# PADCFG_CTRL_MCU_PADCFG_CTRL_MMR_CFG0_04080000h register map
Vendor: Texas Instruments
Peripheral module from a debugger description file (folder AM275x).
Registers are 32-bit, access per field, reset 0x214007 unless marked. A register's access mark holds for its fields unless they carry their own. Offsets are as the file gives them; lines under a group give offsets from that group; [hi:lo] are bit positions; {n}, {i} and the like mark numbered series; 'fields as' and 'values as' point back to an identical list; <NAME> marks a mode.

## mcu_padcfg_ctrl_mmr_CFG0 (part 1 of 3)
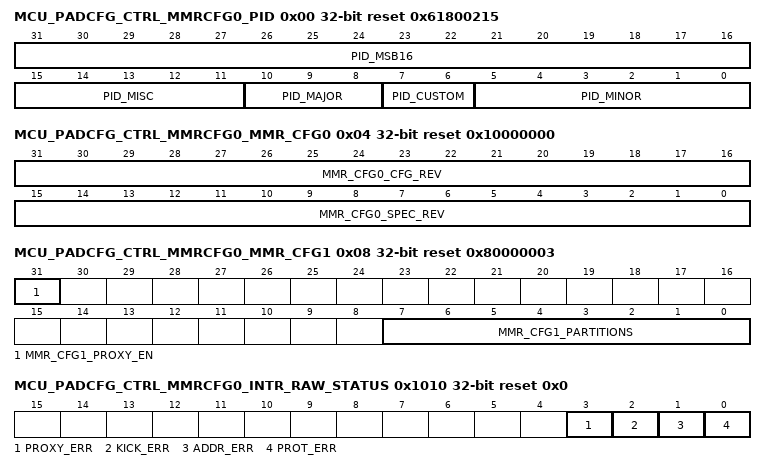
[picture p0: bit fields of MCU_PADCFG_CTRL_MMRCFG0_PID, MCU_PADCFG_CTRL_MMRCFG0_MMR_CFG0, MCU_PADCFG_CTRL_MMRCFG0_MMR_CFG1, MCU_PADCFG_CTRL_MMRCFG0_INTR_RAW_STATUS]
0x00 MCU_PADCFG_CTRL_MMRCFG0_PID ro reset 0x61800215
  [31:16] PID_MSB16 — Reset Source: mod_g_rst_n
  [15:11] PID_MISC — Reset Source: mod_g_rst_n
  [10:8] PID_MAJOR — Reset Source: mod_g_rst_n
  [7:6] PID_CUSTOM — Reset Source: mod_g_rst_n
  [5:0] PID_MINOR — Reset Source: mod_g_rst_n
0x04 MCU_PADCFG_CTRL_MMRCFG0_MMR_CFG0 ro reset 0x10000000 — Indicates the version of the CFG used to create the MMR Module
  [31:16] MMR_CFG0_CFG_REV — Major configuration release Reset Source: mod_por_rst_n
  [15:0] MMR_CFG0_SPEC_REV — Minor spec-only revision. Deprecated.Was intended to reflect non-RTL updates in the printed Spec but this can't be reflected in the MMR read value without an RTL change when post RTL descriptions are pushed into the VPS. Reset Source: mod_por_rst_n
0x08 MCU_PADCFG_CTRL_MMRCFG0_MMR_CFG1 ro reset 0x80000003 — Indicates the MMR configuration
  [31] MMR_CFG1_PROXY_EN — Proxy addressing enabled Reset Source: mod_por_rst_n
  [7:0] MMR_CFG1_PARTITIONS — Indicates present partitions Reset Source: mod_por_rst_n
0x1008 MCU_PADCFG_CTRL_MMRCFG0_LOCK0_KICK0 rw reset 0x0
  [31:0] LOCK0_KICK0 — - KICK0 component Reset Source: mod_g_rst_n
0x100C MCU_PADCFG_CTRL_MMRCFG0_LOCK0_KICK1 rw reset 0x0
  [31:0] LOCK0_KICK1 — - KICK1 component Reset Source: mod_g_rst_n
0x1010 MCU_PADCFG_CTRL_MMRCFG0_INTR_RAW_STATUS access not given reset 0x0
  [3] PROXY_ERR — Proxy0 access violation error. Raw status is read. Write a 1 to set the status. Writing a 0 has no effect. Reset Source: mod_g_rst_n (access R/W1TS)
  [2] KICK_ERR — Kick access violation error. Raw status is read. Write a 1 to set the status. Writing a 0 has no effect. Reset Source: mod_g_rst_n (access R/W1TS)
  [1] ADDR_ERR — Addressing violation error. Raw status is read. Write a 1 to set the status. Writing a 0 has no effect. Reset Source: mod_g_rst_n (access R/W1TS)
  [0] PROT_ERR — Protection violation error. Raw status is read. Write a 1 to set the status. Writing a 0 has no effect. Reset Source: mod_g_rst_n (access R/W1TS)
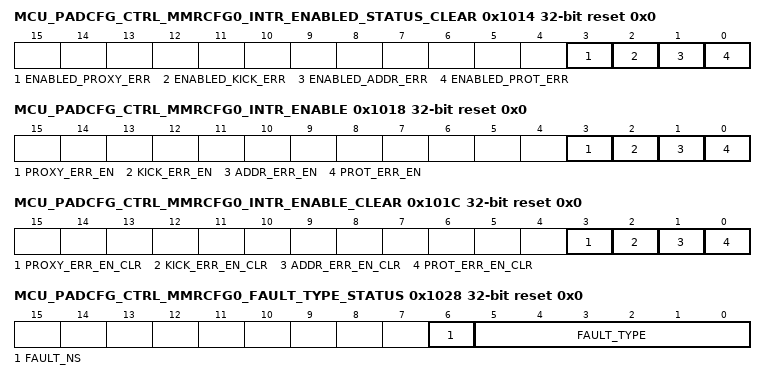
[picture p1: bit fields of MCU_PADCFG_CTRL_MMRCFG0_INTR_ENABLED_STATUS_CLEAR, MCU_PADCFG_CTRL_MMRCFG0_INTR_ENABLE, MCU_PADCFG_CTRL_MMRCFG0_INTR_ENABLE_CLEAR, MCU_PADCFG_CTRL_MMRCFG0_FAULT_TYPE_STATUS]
0x1014 MCU_PADCFG_CTRL_MMRCFG0_INTR_ENABLED_STATUS_CLEAR access not given reset 0x0
  [3] ENABLED_PROXY_ERR — Proxy0 access violation error. Enabled status is read. Write a 1 to clear the status. Writing a 0 has no effect. Reset Source: mod_g_rst_n (access R/W1TC)
  [2] ENABLED_KICK_ERR — Kick access violation error. Enabled status is read. Write a 1 to clear the status. Writing a 0 has no effect. Reset Source: mod_g_rst_n (access R/W1TC)
  [1] ENABLED_ADDR_ERR — Addressing violation error. Enabled status is read. Write a 1 to clear the status. Writing a 0 has no effect. Reset Source: mod_g_rst_n (access R/W1TC)
  [0] ENABLED_PROT_ERR — Protection violation error. Enabled status is read. Write a 1 to clear the status. Writing a 0 has no effect. Reset Source: mod_g_rst_n (access R/W1TC)
0x1018 MCU_PADCFG_CTRL_MMRCFG0_INTR_ENABLE access not given reset 0x0
  [3] PROXY_ERR_EN — Proxy0 access violation error enable. Write a 1 to set the enable. Writing a 0 has no effect. Reset Source: mod_g_rst_n (access R/W1TS)
  [2] KICK_ERR_EN — Kick access violation error enable. Write a 1 to set the enable. Writing a 0 has no effect. Reset Source: mod_g_rst_n (access R/W1TS)
  [1] ADDR_ERR_EN — Addressing violation error enable. Write a 1 to set the enable. Writing a 0 has no effect. Reset Source: mod_g_rst_n (access R/W1TS)
  [0] PROT_ERR_EN — Protection violation error enable. Write a 1 to set the enable. Writing a 0 has no effect. Reset Source: mod_g_rst_n (access R/W1TS)
0x101C MCU_PADCFG_CTRL_MMRCFG0_INTR_ENABLE_CLEAR access not given reset 0x0
  [3] PROXY_ERR_EN_CLR — Proxy0 access violation error enable clear. Write a 1 to clear the enable. Writing a 0 has no effect. Reset Source: mod_g_rst_n (access R/W1TC)
  [2] KICK_ERR_EN_CLR — Kick access violation error enable clear. Write a 1 to clear the enable. Writing a 0 has no effect. Reset Source: mod_g_rst_n (access R/W1TC)
  [1] ADDR_ERR_EN_CLR — Addressing violation error enable clear. Write a 1 to clear the enable. Writing a 0 has no effect. Reset Source: mod_g_rst_n (access R/W1TC)
  [0] PROT_ERR_EN_CLR — Protection violation error enable clear. Write a 1 to clear the enable. Writing a 0 has no effect. Reset Source: mod_g_rst_n (access R/W1TC)
0x1020 MCU_PADCFG_CTRL_MMRCFG0_EOI rw reset 0x0
  [7:0] EOI_VECTOR — EOI vector value. Write this with interrupt distribution value in the chip. Reset Source: mod_g_rst_n
0x1024 MCU_PADCFG_CTRL_MMRCFG0_FAULT_ADDRESS ro reset 0x0
  [31:0] FAULT_ADDR — Fault Address. Reset Source: mod_g_rst_n
0x1028 MCU_PADCFG_CTRL_MMRCFG0_FAULT_TYPE_STATUS ro reset 0x0
  [6] FAULT_NS — Non-secure access. Reset Source: mod_g_rst_n
  [5:0] FAULT_TYPE — Fault Type 10_0000 = Supervisor read fault - priv = 1 dir = 1 dtype != 1 01_0000 = Supervisor write fault - priv = 1 dir = 0 00_1000 = Supervisor execute fault - priv = 1 dir = 1 dtype = 1 00_0100 = User read fault - priv = 0 dir = 1 dtype = 1 00_0010 = User write fault - priv = 0 dir = 0 00_0001 = User execute fault - priv = 0 dir = 1 dtype = 1 00_0000 = No fault Reset Source: mod_g_rst_n
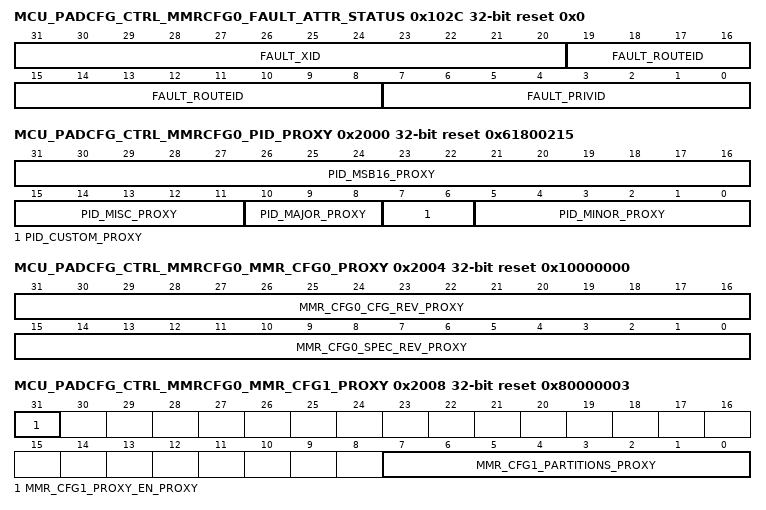
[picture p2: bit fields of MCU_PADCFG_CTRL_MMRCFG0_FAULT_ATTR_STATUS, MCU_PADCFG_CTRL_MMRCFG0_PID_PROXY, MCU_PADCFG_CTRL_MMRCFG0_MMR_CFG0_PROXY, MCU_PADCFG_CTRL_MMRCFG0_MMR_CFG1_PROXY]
0x102C MCU_PADCFG_CTRL_MMRCFG0_FAULT_ATTR_STATUS ro reset 0x0
  [31:20] FAULT_XID — XID. Reset Source: mod_g_rst_n
  [19:8] FAULT_ROUTEID — Route ID. Reset Source: mod_g_rst_n
  [7:0] FAULT_PRIVID — Privilege ID. Reset Source: mod_g_rst_n
0x1030 MCU_PADCFG_CTRL_MMRCFG0_FAULT_CLEAR wo reset 0x0
  [0] FAULT_CLR — Fault clear. Writing a 1 clears the current fault. Writing a 0 has no effect. Reset Source: mod_g_rst_n
0x1100 MCU_PADCFG_CTRL_MMRCFG0_CLAIMREG_P0_R0_READONLY ro reset 0x0
  [31:0] CLAIMREG_P0_R0_READONLY — Claim bits for Partition 0 Reset Source: mod_g_rst_n
0x2000 MCU_PADCFG_CTRL_MMRCFG0_PID_PROXY ro reset 0x61800215
  [31:16] PID_MSB16_PROXY — Reset Source: mod_g_rst_n
  [15:11] PID_MISC_PROXY — Reset Source: mod_g_rst_n
  [10:8] PID_MAJOR_PROXY — Reset Source: mod_g_rst_n
  [7:6] PID_CUSTOM_PROXY — Reset Source: mod_g_rst_n
  [5:0] PID_MINOR_PROXY — Reset Source: mod_g_rst_n
0x2004 MCU_PADCFG_CTRL_MMRCFG0_MMR_CFG0_PROXY ro reset 0x10000000 — Indicates the version of the CFG used to create the MMR Module
  [31:16] MMR_CFG0_CFG_REV_PROXY — Major configuration release Reset Source: mod_por_rst_n
  [15:0] MMR_CFG0_SPEC_REV_PROXY — Minor spec-only revision. Deprecated.Was intended to reflect non-RTL updates in the printed Spec but this can't be reflected in the MMR read value without an RTL change when post RTL descriptions are pushed into the VPS. Reset Source: mod_por_rst_n
0x2008 MCU_PADCFG_CTRL_MMRCFG0_MMR_CFG1_PROXY ro reset 0x80000003 — Indicates the MMR configuration
  [31] MMR_CFG1_PROXY_EN_PROXY — Proxy addressing enabled Reset Source: mod_por_rst_n
  [7:0] MMR_CFG1_PARTITIONS_PROXY — Indicates present partitions Reset Source: mod_por_rst_n
0x3008 MCU_PADCFG_CTRL_MMRCFG0_LOCK0_KICK0_PROXY rw reset 0x0
  [31:0] LOCK0_KICK0_PROXY — - KICK0 component Reset Source: mod_g_rst_n
0x300C MCU_PADCFG_CTRL_MMRCFG0_LOCK0_KICK1_PROXY rw reset 0x0
  [31:0] LOCK0_KICK1_PROXY — - KICK1 component Reset Source: mod_g_rst_n
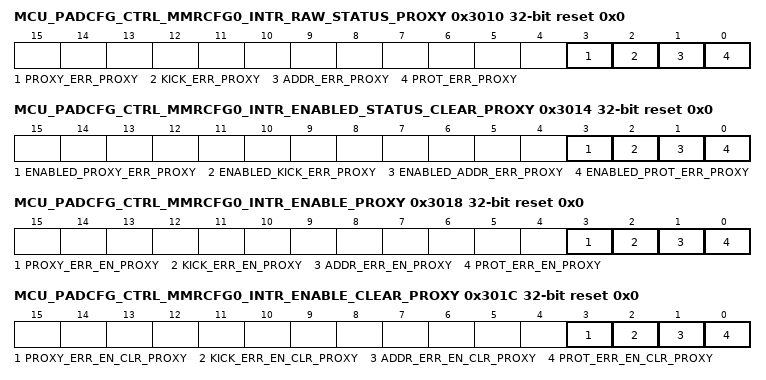
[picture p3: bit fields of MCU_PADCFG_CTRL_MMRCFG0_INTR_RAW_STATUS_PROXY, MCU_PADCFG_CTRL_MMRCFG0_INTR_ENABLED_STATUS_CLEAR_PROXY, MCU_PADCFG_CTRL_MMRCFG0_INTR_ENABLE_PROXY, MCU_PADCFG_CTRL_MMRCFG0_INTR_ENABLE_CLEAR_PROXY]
0x3010 MCU_PADCFG_CTRL_MMRCFG0_INTR_RAW_STATUS_PROXY access not given reset 0x0
  [3] PROXY_ERR_PROXY — Proxy0 access violation error. Raw status is read. Write a 1 to set the status. Writing a 0 has no effect. Reset Source: mod_g_rst_n (access R/W1TS)
  [2] KICK_ERR_PROXY — Kick access violation error. Raw status is read. Write a 1 to set the status. Writing a 0 has no effect. Reset Source: mod_g_rst_n (access R/W1TS)
  [1] ADDR_ERR_PROXY — Addressing violation error. Raw status is read. Write a 1 to set the status. Writing a 0 has no effect. Reset Source: mod_g_rst_n (access R/W1TS)
  [0] PROT_ERR_PROXY — Protection violation error. Raw status is read. Write a 1 to set the status. Writing a 0 has no effect. Reset Source: mod_g_rst_n (access R/W1TS)
0x3014 MCU_PADCFG_CTRL_MMRCFG0_INTR_ENABLED_STATUS_CLEAR_PROXY access not given reset 0x0
  [3] ENABLED_PROXY_ERR_PROXY — Proxy0 access violation error. Enabled status is read. Write a 1 to clear the status. Writing a 0 has no effect. Reset Source: mod_g_rst_n (access R/W1TC)
  [2] ENABLED_KICK_ERR_PROXY — Kick access violation error. Enabled status is read. Write a 1 to clear the status. Writing a 0 has no effect. Reset Source: mod_g_rst_n (access R/W1TC)
  [1] ENABLED_ADDR_ERR_PROXY — Addressing violation error. Enabled status is read. Write a 1 to clear the status. Writing a 0 has no effect. Reset Source: mod_g_rst_n (access R/W1TC)
  [0] ENABLED_PROT_ERR_PROXY — Protection violation error. Enabled status is read. Write a 1 to clear the status. Writing a 0 has no effect. Reset Source: mod_g_rst_n (access R/W1TC)
0x3018 MCU_PADCFG_CTRL_MMRCFG0_INTR_ENABLE_PROXY access not given reset 0x0
  [3] PROXY_ERR_EN_PROXY — Proxy0 access violation error enable. Write a 1 to set the enable. Writing a 0 has no effect. Reset Source: mod_g_rst_n (access R/W1TS)
  [2] KICK_ERR_EN_PROXY — Kick access violation error enable. Write a 1 to set the enable. Writing a 0 has no effect. Reset Source: mod_g_rst_n (access R/W1TS)
  [1] ADDR_ERR_EN_PROXY — Addressing violation error enable. Write a 1 to set the enable. Writing a 0 has no effect. Reset Source: mod_g_rst_n (access R/W1TS)
  [0] PROT_ERR_EN_PROXY — Protection violation error enable. Write a 1 to set the enable. Writing a 0 has no effect. Reset Source: mod_g_rst_n (access R/W1TS)
0x301C MCU_PADCFG_CTRL_MMRCFG0_INTR_ENABLE_CLEAR_PROXY access not given reset 0x0
  [3] PROXY_ERR_EN_CLR_PROXY — Proxy0 access violation error enable clear. Write a 1 to clear the enable. Writing a 0 has no effect. Reset Source: mod_g_rst_n (access R/W1TC)
  [2] KICK_ERR_EN_CLR_PROXY — Kick access violation error enable clear. Write a 1 to clear the enable. Writing a 0 has no effect. Reset Source: mod_g_rst_n (access R/W1TC)
  [1] ADDR_ERR_EN_CLR_PROXY — Addressing violation error enable clear. Write a 1 to clear the enable. Writing a 0 has no effect. Reset Source: mod_g_rst_n (access R/W1TC)
  [0] PROT_ERR_EN_CLR_PROXY — Protection violation error enable clear. Write a 1 to clear the enable. Writing a 0 has no effect. Reset Source: mod_g_rst_n (access R/W1TC)
0x3020 MCU_PADCFG_CTRL_MMRCFG0_EOI_PROXY rw reset 0x0
  [7:0] EOI_VECTOR_PROXY — EOI vector value. Write this with interrupt distribution value in the chip. Reset Source: mod_g_rst_n
0x3024 MCU_PADCFG_CTRL_MMRCFG0_FAULT_ADDRESS_PROXY ro reset 0x0
  [31:0] FAULT_ADDR_PROXY — Fault Address. Reset Source: mod_g_rst_n
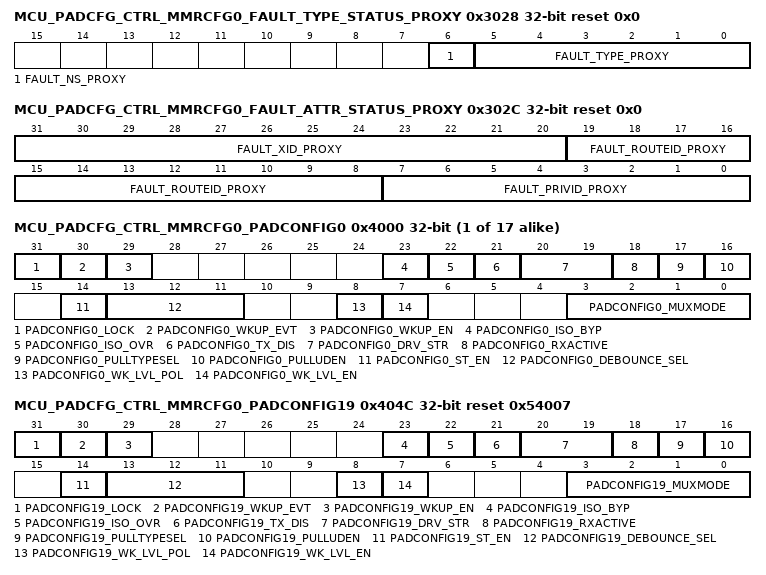
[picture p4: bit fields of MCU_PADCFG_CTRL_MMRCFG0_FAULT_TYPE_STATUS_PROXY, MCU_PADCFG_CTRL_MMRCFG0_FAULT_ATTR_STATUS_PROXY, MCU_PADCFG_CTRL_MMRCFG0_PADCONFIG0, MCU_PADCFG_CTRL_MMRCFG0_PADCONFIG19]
0x3028 MCU_PADCFG_CTRL_MMRCFG0_FAULT_TYPE_STATUS_PROXY ro reset 0x0
  [6] FAULT_NS_PROXY — Non-secure access. Reset Source: mod_g_rst_n
  [5:0] FAULT_TYPE_PROXY — Fault Type 10_0000 = Supervisor read fault - priv = 1 dir = 1 dtype != 1 01_0000 = Supervisor write fault - priv = 1 dir = 0 00_1000 = Supervisor execute fault - priv = 1 dir = 1 dtype = 1 00_0100 = User read fault - priv = 0 dir = 1 dtype = 1 00_0010 = User write fault - priv = 0 dir = 0 00_0001 = User execute fault - priv = 0 dir = 1 dtype = 1 00_0000 = No fault Reset Source: mod_g_rst_n
0x302C MCU_PADCFG_CTRL_MMRCFG0_FAULT_ATTR_STATUS_PROXY ro reset 0x0
  [31:20] FAULT_XID_PROXY — XID. Reset Source: mod_g_rst_n
  [19:8] FAULT_ROUTEID_PROXY — Route ID. Reset Source: mod_g_rst_n
  [7:0] FAULT_PRIVID_PROXY — Privilege ID. Reset Source: mod_g_rst_n
0x3030 MCU_PADCFG_CTRL_MMRCFG0_FAULT_CLEAR_PROXY wo reset 0x0
  [0] FAULT_CLR_PROXY — Fault clear. Writing a 1 clears the current fault. Writing a 0 has no effect. Reset Source: mod_g_rst_n
0x3100 MCU_PADCFG_CTRL_MMRCFG0_CLAIMREG_P0_R0 rw reset 0x0
  [31:0] CLAIMREG_P0_R0 — Claim bits for Partition 0 Reset Source: mod_g_rst_n
{0x4000+4i} MCU_PADCFG_CTRL_MMRCFG0_PADCONFIG{i} (i=0..16) — Register to control pin configuration and muxing
  [31] PADCONFIG{i}_LOCK rw — Lock 0 - Padconfig register is unlocked 1 - Padconfig register is locked from further writes Reset Source: mod_por_rst_n
  [30] PADCONFIG{i}_WKUP_EVT ro — Wakeup event status 0 - No wake event on pin 1 - Wake event occurred on pin Reset Source: mod_por_rst_n
  [29] PADCONFIG{i}_WKUP_EN rw — Wakeup enable 0 - Wakeup operation disabled 1 - Wakeup operation enabled Reset Source: mod_por_rst_n
  [23] PADCONFIG{i}_ISO_BYP rw — Isolation Bypass0 - IO isolation is preserved1 - IO isolation is bypassed Reset Source: mod_por_rst_n
  [22] PADCONFIG{i}_ISO_OVR rw — Isolation Override0 - IO isolation is preserved1 - IO isolation is overridden Reset Source: mod_por_rst_n
  [21] PADCONFIG{i}_TX_DIS rw — Driver Disable0 - Driver is enabled1 - Driver is disabled Reset Source: mod_por_rst_n
  [20:19] PADCONFIG{i}_DRV_STR rw — Drive Strength Control . Selects the drive strength value for LVCMOS pins. (Does not apply to other pin types) Reset Source: mod_por_rst_n
  [18] PADCONFIG{i}_RXACTIVE rw — Input enable for the Pad0 - Receiver disabled1 - Receiver enabled Reset Source: mod_por_rst_n
  [17] PADCONFIG{i}_PULLTYPESEL rw — Pad Pullup / Pulldown type selection0 - Pulldown selected1 - Pullup selected Reset Source: mod_por_rst_n
  [16] PADCONFIG{i}_PULLUDEN rw — Pad Pullup / Pulldown enable. This is an active low signal.0 - Pullup / Pulldown enabled1 - Pullup / Pulldown disabled Reset Source: mod_por_rst_n
  [14] PADCONFIG{i}_ST_EN rw — Receiver Schmitt Trigger enable 0 - Schmitt trigger input disabled 1 - Schmitt trigger input enabled Reset Source: mod_por_rst_n
  [13:11] PADCONFIG{i}_DEBOUNCE_SEL rw — Selects the debouce period for the pad.Field values (others are reserved):3'b000 - No debounce enabled 3'b001 - Use DBOUNCE_CFG1 register value3'b010 - Use DBOUNCE_CFG2 register value3'b011 - Use DBOUNCE_CFG3 register value3'b100 - Use DBOUNCE_CFG4 register value3'b101 - Use DBOUNCE_CFG5 register value3'b110 - Use DBOUNCE_CFG6 register value3'b'111 - Reserved Reset Source: mod_por_rst_n
  [8] PADCONFIG{i}_WK_LVL_POL rw — Level Sensitive Wakeup PolarityThis bit is not relevant unless wk_lvl_en is set to 1'b1.0 - Low. A low (0) value on the pin causes a wakeup1 - High. A high (1) value on the pin causes a wakeup Reset Source: mod_por_rst_n
  [7] PADCONFIG{i}_WK_LVL_EN rw — Level Sensitive Wakeup Enable0 - Disabled. Wakeup is triggered by change of the pin input value1 - Enabled. Wakeup is triggered when the pin matches the value specified by wk_lvl_pol. The chosen polarity must be maintained. (e.g. until wakeup completion is confirmed) Reset Source: mod_por_rst_n
  [3:0] PADCONFIG{i}_MUXMODE rw — Pad functional signal mux selectionField values (others are reserved):4'h0 - Mux Mode 04'h1 - Mux Mode 14'h2 - Mux Mode 24'h3 - Mux Mode 34'h4 - Mux Mode 44'h5 - Mux Mode 54'h6 - Mux Mode 64'h7 - Mux Mode 74'h8 - Mux Mode 84'h9 - Mux Mode 94'hA - Mux Mode 104'hB - Mux Mode 114'hC - Mux Mode 124'hD - Mux Mode 134'hE - Mux Mode 144'hF - Mux Mode 15 Reset Source: mod_por_rst_n
0x404C MCU_PADCFG_CTRL_MMRCFG0_PADCONFIG19 reset 0x54007 — Register to control pin configuration and muxing
  [31] PADCONFIG19_LOCK rw — Lock 0 - Padconfig register is unlocked 1 - Padconfig register is locked from further writes Reset Source: mod_por_rst_n
  [30] PADCONFIG19_WKUP_EVT ro — Wakeup event status 0 - No wake event on pin 1 - Wake event occurred on pin Reset Source: mod_por_rst_n
  [29] PADCONFIG19_WKUP_EN rw — Wakeup enable 0 - Wakeup operation disabled 1 - Wakeup operation enabled Reset Source: mod_por_rst_n
  [23] PADCONFIG19_ISO_BYP rw — Isolation Bypass0 - IO isolation is preserved1 - IO isolation is bypassed Reset Source: mod_por_rst_n
  [22] PADCONFIG19_ISO_OVR rw — Isolation Override0 - IO isolation is preserved1 - IO isolation is overridden Reset Source: mod_por_rst_n
  [21] PADCONFIG19_TX_DIS rw — Driver Disable0 - Driver is enabled1 - Driver is disabled Reset Source: mod_por_rst_n
  [20:19] PADCONFIG19_DRV_STR rw — Drive Strength Control . Selects the drive strength value for LVCMOS pins. (Does not apply to other pin types) Reset Source: mod_por_rst_n
  [18] PADCONFIG19_RXACTIVE rw — Input enable for the Pad0 - Receiver disabled1 - Receiver enabled Reset Source: mod_por_rst_n
  [17] PADCONFIG19_PULLTYPESEL rw — Pad Pullup / Pulldown type selection0 - Pulldown selected1 - Pullup selected Reset Source: mod_por_rst_n
  [16] PADCONFIG19_PULLUDEN rw — Pad Pullup / Pulldown enable. This is an active low signal.0 - Pullup / Pulldown enabled1 - Pullup / Pulldown disabled Reset Source: mod_por_rst_n
  [14] PADCONFIG19_ST_EN rw — Receiver Schmitt Trigger enable 0 - Schmitt trigger input disabled 1 - Schmitt trigger input enabled Reset Source: mod_por_rst_n
  [13:11] PADCONFIG19_DEBOUNCE_SEL rw — Selects the debouce period for the pad.Field values (others are reserved):3'b000 - No debounce enabled 3'b001 - Use DBOUNCE_CFG1 register value3'b010 - Use DBOUNCE_CFG2 register value3'b011 - Use DBOUNCE_CFG3 register value3'b100 - Use DBOUNCE_CFG4 register value3'b101 - Use DBOUNCE_CFG5 register value3'b110 - Use DBOUNCE_CFG6 register value3'b'111 - Reserved Reset Source: mod_por_rst_n
  [8] PADCONFIG19_WK_LVL_POL rw — Level Sensitive Wakeup PolarityThis bit is not relevant unless wk_lvl_en is set to 1'b1.0 - Low. A low (0) value on the pin causes a wakeup1 - High. A high (1) value on the pin causes a wakeup Reset Source: mod_por_rst_n
  [7] PADCONFIG19_WK_LVL_EN rw — Level Sensitive Wakeup Enable0 - Disabled. Wakeup is triggered by change of the pin input value1 - Enabled. Wakeup is triggered when the pin matches the value specified by wk_lvl_pol. The chosen polarity must be maintained. (e.g. until wakeup completion is confirmed) Reset Source: mod_por_rst_n
  [3:0] PADCONFIG19_MUXMODE rw — Pad functional signal mux selectionField values (others are reserved):4'h0 - Mux Mode 04'h1 - Mux Mode 14'h2 - Mux Mode 24'h3 - Mux Mode 34'h4 - Mux Mode 44'h5 - Mux Mode 54'h6 - Mux Mode 64'h7 - Mux Mode 74'h8 - Mux Mode 84'h9 - Mux Mode 94'hA - Mux Mode 104'hB - Mux Mode 114'hC - Mux Mode 124'hD - Mux Mode 134'hE - Mux Mode 144'hF - Mux Mode 15 Reset Source: mod_por_rst_n
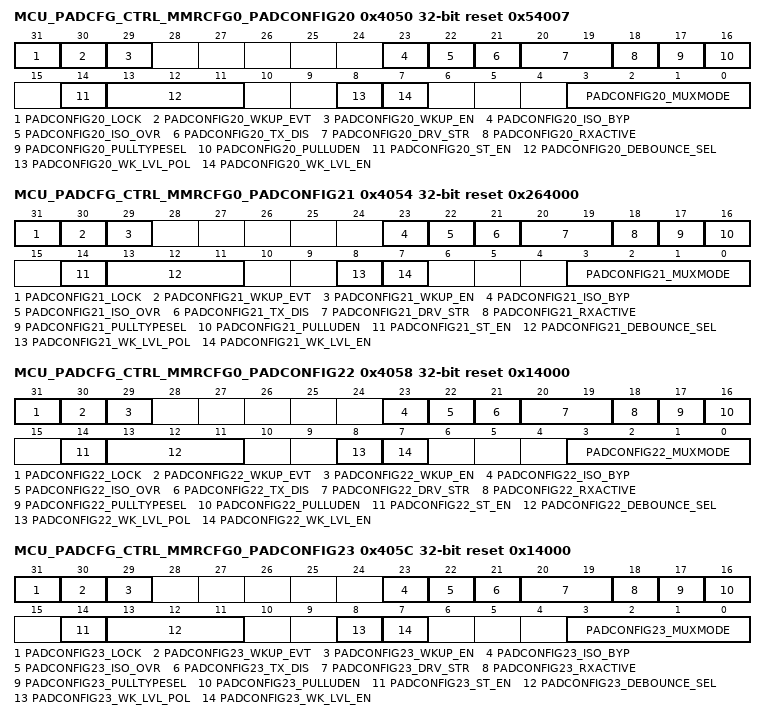
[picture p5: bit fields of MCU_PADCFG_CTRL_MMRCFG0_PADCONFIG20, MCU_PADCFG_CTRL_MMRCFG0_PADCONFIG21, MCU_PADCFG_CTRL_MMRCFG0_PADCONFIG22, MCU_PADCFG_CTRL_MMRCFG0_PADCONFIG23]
0x4050 MCU_PADCFG_CTRL_MMRCFG0_PADCONFIG20 reset 0x54007 — Register to control pin configuration and muxing
  [31] PADCONFIG20_LOCK rw — Lock 0 - Padconfig register is unlocked 1 - Padconfig register is locked from further writes Reset Source: mod_por_rst_n
  [30] PADCONFIG20_WKUP_EVT ro — Wakeup event status 0 - No wake event on pin 1 - Wake event occurred on pin Reset Source: mod_por_rst_n
  [29] PADCONFIG20_WKUP_EN rw — Wakeup enable 0 - Wakeup operation disabled 1 - Wakeup operation enabled Reset Source: mod_por_rst_n
  [23] PADCONFIG20_ISO_BYP rw — Isolation Bypass0 - IO isolation is preserved1 - IO isolation is bypassed Reset Source: mod_por_rst_n
  [22] PADCONFIG20_ISO_OVR rw — Isolation Override0 - IO isolation is preserved1 - IO isolation is overridden Reset Source: mod_por_rst_n
  [21] PADCONFIG20_TX_DIS rw — Driver Disable0 - Driver is enabled1 - Driver is disabled Reset Source: mod_por_rst_n
  [20:19] PADCONFIG20_DRV_STR rw — Drive Strength Control . Selects the drive strength value for LVCMOS pins. (Does not apply to other pin types) Reset Source: mod_por_rst_n
  [18] PADCONFIG20_RXACTIVE rw — Input enable for the Pad0 - Receiver disabled1 - Receiver enabled Reset Source: mod_por_rst_n
  [17] PADCONFIG20_PULLTYPESEL rw — Pad Pullup / Pulldown type selection0 - Pulldown selected1 - Pullup selected Reset Source: mod_por_rst_n
  [16] PADCONFIG20_PULLUDEN rw — Pad Pullup / Pulldown enable. This is an active low signal.0 - Pullup / Pulldown enabled1 - Pullup / Pulldown disabled Reset Source: mod_por_rst_n
  [14] PADCONFIG20_ST_EN rw — Receiver Schmitt Trigger enable 0 - Schmitt trigger input disabled 1 - Schmitt trigger input enabled Reset Source: mod_por_rst_n
  [13:11] PADCONFIG20_DEBOUNCE_SEL rw — Selects the debouce period for the pad.Field values (others are reserved):3'b000 - No debounce enabled 3'b001 - Use DBOUNCE_CFG1 register value3'b010 - Use DBOUNCE_CFG2 register value3'b011 - Use DBOUNCE_CFG3 register value3'b100 - Use DBOUNCE_CFG4 register value3'b101 - Use DBOUNCE_CFG5 register value3'b110 - Use DBOUNCE_CFG6 register value3'b'111 - Reserved Reset Source: mod_por_rst_n
  [8] PADCONFIG20_WK_LVL_POL rw — Level Sensitive Wakeup PolarityThis bit is not relevant unless wk_lvl_en is set to 1'b1.0 - Low. A low (0) value on the pin causes a wakeup1 - High. A high (1) value on the pin causes a wakeup Reset Source: mod_por_rst_n
  [7] PADCONFIG20_WK_LVL_EN rw — Level Sensitive Wakeup Enable0 - Disabled. Wakeup is triggered by change of the pin input value1 - Enabled. Wakeup is triggered when the pin matches the value specified by wk_lvl_pol. The chosen polarity must be maintained. (e.g. until wakeup completion is confirmed) Reset Source: mod_por_rst_n
  [3:0] PADCONFIG20_MUXMODE rw — Pad functional signal mux selectionField values (others are reserved):4'h0 - Mux Mode 04'h1 - Mux Mode 14'h2 - Mux Mode 24'h3 - Mux Mode 34'h4 - Mux Mode 44'h5 - Mux Mode 54'h6 - Mux Mode 64'h7 - Mux Mode 74'h8 - Mux Mode 84'h9 - Mux Mode 94'hA - Mux Mode 104'hB - Mux Mode 114'hC - Mux Mode 124'hD - Mux Mode 134'hE - Mux Mode 144'hF - Mux Mode 15 Reset Source: mod_por_rst_n
0x4054 MCU_PADCFG_CTRL_MMRCFG0_PADCONFIG21 reset 0x264000 — Register to control pin configuration and muxing
  [31] PADCONFIG21_LOCK rw — Lock 0 - Padconfig register is unlocked 1 - Padconfig register is locked from further writes Reset Source: mod_por_rst_n
  [30] PADCONFIG21_WKUP_EVT ro — Wakeup event status 0 - No wake event on pin 1 - Wake event occurred on pin Reset Source: mod_por_rst_n
  [29] PADCONFIG21_WKUP_EN rw — Wakeup enable 0 - Wakeup operation disabled 1 - Wakeup operation enabled Reset Source: mod_por_rst_n
  [23] PADCONFIG21_ISO_BYP rw — Isolation Bypass0 - IO isolation is preserved1 - IO isolation is bypassed Reset Source: mod_por_rst_n
  [22] PADCONFIG21_ISO_OVR rw — Isolation Override0 - IO isolation is preserved1 - IO isolation is overridden Reset Source: mod_por_rst_n
  [21] PADCONFIG21_TX_DIS rw — Driver Disable0 - Driver is enabled1 - Driver is disabled Reset Source: mod_por_rst_n
  [20:19] PADCONFIG21_DRV_STR rw — Drive Strength Control . Selects the drive strength value for LVCMOS pins. (Does not apply to other pin types) Reset Source: mod_por_rst_n
  [18] PADCONFIG21_RXACTIVE rw — Input enable for the Pad0 - Receiver disabled1 - Receiver enabled Reset Source: mod_por_rst_n
  [17] PADCONFIG21_PULLTYPESEL rw — Pad Pullup / Pulldown type selection0 - Pulldown selected1 - Pullup selected Reset Source: mod_por_rst_n
  [16] PADCONFIG21_PULLUDEN rw — Pad Pullup / Pulldown enable. This is an active low signal.0 - Pullup / Pulldown enabled1 - Pullup / Pulldown disabled Reset Source: mod_por_rst_n
  [14] PADCONFIG21_ST_EN rw — Receiver Schmitt Trigger enable 0 - Schmitt trigger input disabled 1 - Schmitt trigger input enabled Reset Source: mod_por_rst_n
  [13:11] PADCONFIG21_DEBOUNCE_SEL rw — Selects the debouce period for the pad.Field values (others are reserved):3'b000 - No debounce enabled 3'b001 - Use DBOUNCE_CFG1 register value3'b010 - Use DBOUNCE_CFG2 register value3'b011 - Use DBOUNCE_CFG3 register value3'b100 - Use DBOUNCE_CFG4 register value3'b101 - Use DBOUNCE_CFG5 register value3'b110 - Use DBOUNCE_CFG6 register value3'b'111 - Reserved Reset Source: mod_por_rst_n
  [8] PADCONFIG21_WK_LVL_POL rw — Level Sensitive Wakeup PolarityThis bit is not relevant unless wk_lvl_en is set to 1'b1.0 - Low. A low (0) value on the pin causes a wakeup1 - High. A high (1) value on the pin causes a wakeup Reset Source: mod_por_rst_n
  [7] PADCONFIG21_WK_LVL_EN rw — Level Sensitive Wakeup Enable0 - Disabled. Wakeup is triggered by change of the pin input value1 - Enabled. Wakeup is triggered when the pin matches the value specified by wk_lvl_pol. The chosen polarity must be maintained. (e.g. until wakeup completion is confirmed) Reset Source: mod_por_rst_n
  [3:0] PADCONFIG21_MUXMODE rw — Pad functional signal mux selectionField values (others are reserved):4'h0 - Mux Mode 04'h1 - Mux Mode 14'h2 - Mux Mode 24'h3 - Mux Mode 34'h4 - Mux Mode 44'h5 - Mux Mode 54'h6 - Mux Mode 64'h7 - Mux Mode 74'h8 - Mux Mode 84'h9 - Mux Mode 94'hA - Mux Mode 104'hB - Mux Mode 114'hC - Mux Mode 124'hD - Mux Mode 134'hE - Mux Mode 144'hF - Mux Mode 15 Reset Source: mod_por_rst_n
0x4058 MCU_PADCFG_CTRL_MMRCFG0_PADCONFIG22 reset 0x14000 — Register to control pin configuration and muxing
  [31] PADCONFIG22_LOCK rw — Lock 0 - Padconfig register is unlocked 1 - Padconfig register is locked from further writes Reset Source: mod_por_rst_n
  [30] PADCONFIG22_WKUP_EVT ro — Wakeup event status 0 - No wake event on pin 1 - Wake event occurred on pin Reset Source: mod_por_rst_n
  [29] PADCONFIG22_WKUP_EN rw — Wakeup enable 0 - Wakeup operation disabled 1 - Wakeup operation enabled Reset Source: mod_por_rst_n
  [23] PADCONFIG22_ISO_BYP rw — Isolation Bypass0 - IO isolation is preserved1 - IO isolation is bypassed Reset Source: mod_por_rst_n
  [22] PADCONFIG22_ISO_OVR rw — Isolation Override0 - IO isolation is preserved1 - IO isolation is overridden Reset Source: mod_por_rst_n
  [21] PADCONFIG22_TX_DIS rw — Driver Disable0 - Driver is enabled1 - Driver is disabled Reset Source: mod_por_rst_n
  [20:19] PADCONFIG22_DRV_STR rw — Drive Strength Control . Selects the drive strength value for LVCMOS pins. (Does not apply to other pin types) Reset Source: mod_por_rst_n
  [18] PADCONFIG22_RXACTIVE rw — Input enable for the Pad0 - Receiver disabled1 - Receiver enabled Reset Source: mod_por_rst_n
  [17] PADCONFIG22_PULLTYPESEL rw — Pad Pullup / Pulldown type selection0 - Pulldown selected1 - Pullup selected Reset Source: mod_por_rst_n
  [16] PADCONFIG22_PULLUDEN rw — Pad Pullup / Pulldown enable. This is an active low signal.0 - Pullup / Pulldown enabled1 - Pullup / Pulldown disabled Reset Source: mod_por_rst_n
  [14] PADCONFIG22_ST_EN rw — Receiver Schmitt Trigger enable 0 - Schmitt trigger input disabled 1 - Schmitt trigger input enabled Reset Source: mod_por_rst_n
  [13:11] PADCONFIG22_DEBOUNCE_SEL rw — Selects the debouce period for the pad.Field values (others are reserved):3'b000 - No debounce enabled 3'b001 - Use DBOUNCE_CFG1 register value3'b010 - Use DBOUNCE_CFG2 register value3'b011 - Use DBOUNCE_CFG3 register value3'b100 - Use DBOUNCE_CFG4 register value3'b101 - Use DBOUNCE_CFG5 register value3'b110 - Use DBOUNCE_CFG6 register value3'b'111 - Reserved Reset Source: mod_por_rst_n
  [8] PADCONFIG22_WK_LVL_POL rw — Level Sensitive Wakeup PolarityThis bit is not relevant unless wk_lvl_en is set to 1'b1.0 - Low. A low (0) value on the pin causes a wakeup1 - High. A high (1) value on the pin causes a wakeup Reset Source: mod_por_rst_n
  [7] PADCONFIG22_WK_LVL_EN rw — Level Sensitive Wakeup Enable0 - Disabled. Wakeup is triggered by change of the pin input value1 - Enabled. Wakeup is triggered when the pin matches the value specified by wk_lvl_pol. The chosen polarity must be maintained. (e.g. until wakeup completion is confirmed) Reset Source: mod_por_rst_n
  [3:0] PADCONFIG22_MUXMODE rw — Pad functional signal mux selectionField values (others are reserved):4'h0 - Mux Mode 04'h1 - Mux Mode 14'h2 - Mux Mode 24'h3 - Mux Mode 34'h4 - Mux Mode 44'h5 - Mux Mode 54'h6 - Mux Mode 64'h7 - Mux Mode 74'h8 - Mux Mode 84'h9 - Mux Mode 94'hA - Mux Mode 104'hB - Mux Mode 114'hC - Mux Mode 124'hD - Mux Mode 134'hE - Mux Mode 144'hF - Mux Mode 15 Reset Source: mod_por_rst_n
0x405C MCU_PADCFG_CTRL_MMRCFG0_PADCONFIG23 reset 0x14000 — Register to control pin configuration and muxing
  [31] PADCONFIG23_LOCK rw — Lock 0 - Padconfig register is unlocked 1 - Padconfig register is locked from further writes Reset Source: mod_por_rst_n
  [30] PADCONFIG23_WKUP_EVT ro — Wakeup event status 0 - No wake event on pin 1 - Wake event occurred on pin Reset Source: mod_por_rst_n
  [29] PADCONFIG23_WKUP_EN rw — Wakeup enable 0 - Wakeup operation disabled 1 - Wakeup operation enabled Reset Source: mod_por_rst_n
  [23] PADCONFIG23_ISO_BYP rw — Isolation Bypass0 - IO isolation is preserved1 - IO isolation is bypassed Reset Source: mod_por_rst_n
  [22] PADCONFIG23_ISO_OVR rw — Isolation Override0 - IO isolation is preserved1 - IO isolation is overridden Reset Source: mod_por_rst_n
  [21] PADCONFIG23_TX_DIS rw — Driver Disable0 - Driver is enabled1 - Driver is disabled Reset Source: mod_por_rst_n
  [20:19] PADCONFIG23_DRV_STR rw — Drive Strength Control . Selects the drive strength value for LVCMOS pins. (Does not apply to other pin types) Reset Source: mod_por_rst_n
  [18] PADCONFIG23_RXACTIVE rw — Input enable for the Pad0 - Receiver disabled1 - Receiver enabled Reset Source: mod_por_rst_n
  [17] PADCONFIG23_PULLTYPESEL rw — Pad Pullup / Pulldown type selection0 - Pulldown selected1 - Pullup selected Reset Source: mod_por_rst_n
  [16] PADCONFIG23_PULLUDEN rw — Pad Pullup / Pulldown enable. This is an active low signal.0 - Pullup / Pulldown enabled1 - Pullup / Pulldown disabled Reset Source: mod_por_rst_n
  [14] PADCONFIG23_ST_EN rw — Receiver Schmitt Trigger enable 0 - Schmitt trigger input disabled 1 - Schmitt trigger input enabled Reset Source: mod_por_rst_n
  [13:11] PADCONFIG23_DEBOUNCE_SEL rw — Selects the debouce period for the pad.Field values (others are reserved):3'b000 - No debounce enabled 3'b001 - Use DBOUNCE_CFG1 register value3'b010 - Use DBOUNCE_CFG2 register value3'b011 - Use DBOUNCE_CFG3 register value3'b100 - Use DBOUNCE_CFG4 register value3'b101 - Use DBOUNCE_CFG5 register value3'b110 - Use DBOUNCE_CFG6 register value3'b'111 - Reserved Reset Source: mod_por_rst_n
  [8] PADCONFIG23_WK_LVL_POL rw — Level Sensitive Wakeup PolarityThis bit is not relevant unless wk_lvl_en is set to 1'b1.0 - Low. A low (0) value on the pin causes a wakeup1 - High. A high (1) value on the pin causes a wakeup Reset Source: mod_por_rst_n
  [7] PADCONFIG23_WK_LVL_EN rw — Level Sensitive Wakeup Enable0 - Disabled. Wakeup is triggered by change of the pin input value1 - Enabled. Wakeup is triggered when the pin matches the value specified by wk_lvl_pol. The chosen polarity must be maintained. (e.g. until wakeup completion is confirmed) Reset Source: mod_por_rst_n
  [3:0] PADCONFIG23_MUXMODE rw — Pad functional signal mux selectionField values (others are reserved):4'h0 - Mux Mode 04'h1 - Mux Mode 14'h2 - Mux Mode 24'h3 - Mux Mode 34'h4 - Mux Mode 44'h5 - Mux Mode 54'h6 - Mux Mode 64'h7 - Mux Mode 74'h8 - Mux Mode 84'h9 - Mux Mode 94'hA - Mux Mode 104'hB - Mux Mode 114'hC - Mux Mode 124'hD - Mux Mode 134'hE - Mux Mode 144'hF - Mux Mode 15 Reset Source: mod_por_rst_n
